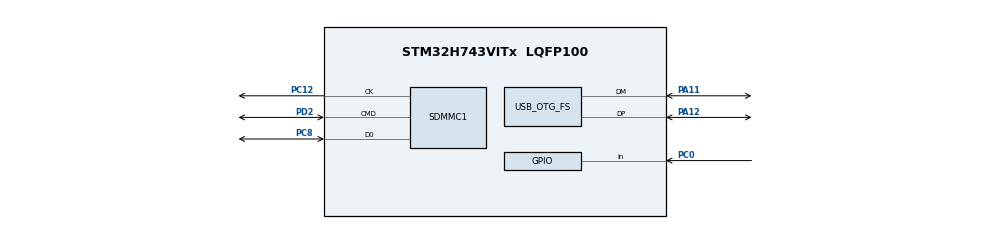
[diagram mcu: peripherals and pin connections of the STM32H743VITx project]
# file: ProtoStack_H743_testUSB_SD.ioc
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FATFS.USE_DMA_CODE_SD=1
Mcu.Family=STM32H7
Mcu.Name=STM32H743VITx
Mcu.Package=LQFP100
NVIC.OTG_FS_IRQn=true\:0\:0\:false\:false\:true\:true\:true\:true
NVIC.PriorityGroup=NVIC_PRIORITYGROUP_4
NVIC.SDMMC1_IRQn=true\:0\:0\:false\:false\:true\:true\:true\:true
PA11.GPIO_Speed=GPIO_SPEED_FREQ_VERY_HIGH
PA11.Mode=Device_Only
PA11.Signal=USB_OTG_FS_DM
PA12.GPIO_Speed=GPIO_SPEED_FREQ_VERY_HIGH
PA12.Mode=Device_Only
PA12.Signal=USB_OTG_FS_DP
PA13\ (JTMS/SWDIO).Mode=Trace_Asynchronous_SW
PA13\ (JTMS/SWDIO).Signal=DEBUG_JTMS-SWDIO
PA14\ (JTCK/SWCLK).Mode=Trace_Asynchronous_SW
PA14\ (JTCK/SWCLK).Signal=DEBUG_JTCK-SWCLK
PB3\ (JTDO/TRACESWO).Mode=Trace_Asynchronous_SW
PB3\ (JTDO/TRACESWO).Signal=DEBUG_JTDO-SWO
PC0.GPIO_PuPd=GPIO_PULLUP
PC0.Signal=GPIO_Input
PC12.GPIO_PuPd=GPIO_PULLUP
PC12.Mode=SD_1_bit
PC12.Signal=SDMMC1_CK
PC8.GPIO_PuPd=GPIO_PULLUP
PC8.Mode=SD_1_bit
PC8.Signal=SDMMC1_D0
PD2.GPIO_PuPd=GPIO_PULLUP
PD2.Mode=SD_1_bit
PD2.Signal=SDMMC1_CMD
PH0-OSC_IN\ (PH0).Mode=HSE-External-Oscillator
PH0-OSC_IN\ (PH0).Signal=RCC_OSC_IN
PH1-OSC_OUT\ (PH1).Mode=HSE-External-Oscillator
PH1-OSC_OUT\ (PH1).Signal=RCC_OSC_OUT
ProjectManager.HeapSize=0x800
ProjectManager.StackSize=0x1600
ProjectManager.TargetToolchain=STM32CubeIDE
RCC.ADCFreq_Value=96000000
RCC.APB1Freq_Value=120000000
RCC.APB2Freq_Value=120000000
RCC.APB3Freq_Value=120000000
RCC.APB4Freq_Value=120000000
RCC.CortexFreq_Value=480000000
RCC.D1PPRE=RCC_APB3_DIV2
RCC.D2PPRE1=RCC_APB1_DIV2
RCC.D2PPRE2=RCC_APB2_DIV2
RCC.D3PPRE=RCC_APB4_DIV2
RCC.DIVM1=4
RCC.DIVM2=16
RCC.DIVN1=160
RCC.DIVN2=128
RCC.DIVR2=8
RCC.EnbaleCSS=true
RCC.HCLKFreq_Value=240000000
RCC.HPRE=RCC_HCLK_DIV2
RCC.HSE_VALUE=24000000
RCC.PLLSourceVirtual=RCC_PLLSOURCE_HSE
RCC.SDMMC1CLockSelection=RCC_SDMMCCLKSOURCE_PLL2
RCC.SYSCLKFreq_VALUE=480000000
RCC.SYSCLKSource=RCC_SYSCLKSOURCE_PLLCLK
RCC.USBCLockSelection=RCC_USBCLKSOURCE_HSI48
RCC.USBFreq_Value=48000000
SDMMC1.ClockDiv=1
USB_DEVICE.CLASS_NAME_FS=MSC
USB_DEVICE.MSC_MEDIA_PACKET-MSC_FS=512
USB_DEVICE.VirtualMode-MSC_FS=Msc
USB_DEVICE.VirtualModeFS=Msc_FS
USB_OTG_FS.VirtualMode=Device_Only
VP_FATFS_VS_SDIO.Mode=SDIO
VP_USB_DEVICE_VS_USB_DEVICE_MSC_FS.Mode=MSC_FS
board=custom

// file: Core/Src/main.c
/* USER CODE BEGIN Header */
/**
  ******************************************************************************
  * @file           : main.c
  * @brief          : Main program body
  ******************************************************************************
  * @attention
  *
  * Copyright (c) 2023 STMicroelectronics.
  * All rights reserved.
  *
  * This software is licensed under terms that can be found in the LICENSE file
  * in the root directory of this software component.
  * If no LICENSE file comes with this software, it is provided AS-IS.
  *
  ******************************************************************************
  */
/* USER CODE END Header */
#include "main.h"
#include "fatfs.h"
#include "sdmmc.h"
#include "usb_device.h"
#include "gpio.h"

void SystemClock_Config(void);

int main(void)
{

  /* MCU Configuration--------------------------------------------------------*/

  /* Reset of all peripherals, Initializes the Flash interface and the Systick. */
  HAL_Init();

  /* Configure the system clock */
  SystemClock_Config();

  /* Initialize all configured peripherals */
  MX_GPIO_Init();
  MX_SDMMC1_SD_Init();
  MX_FATFS_Init();
  MX_USB_DEVICE_Init();

  /* USER CODE BEGIN 2 */

//  HAL_SD_InitCard(&hsd1);
//  HAL_SD_CardInfoTypeDef info;
//  HAL_SD_GetCardInfo(&hsd1, &info);
//  __NOP();
  /* USER CODE END 2 */

  /* Infinite loop */
  while (1)
  {

  }
}

void SystemClock_Config(void)
{
  RCC_OscInitTypeDef RCC_OscInitStruct = {0};
  RCC_ClkInitTypeDef RCC_ClkInitStruct = {0};

  /** Supply configuration update enable
  */
  HAL_PWREx_ConfigSupply(PWR_LDO_SUPPLY);

  /** Configure the main internal regulator output voltage
  */
  __HAL_PWR_VOLTAGESCALING_CONFIG(PWR_REGULATOR_VOLTAGE_SCALE1);

  while(!__HAL_PWR_GET_FLAG(PWR_FLAG_VOSRDY)) {}

  __HAL_RCC_SYSCFG_CLK_ENABLE();
  __HAL_PWR_VOLTAGESCALING_CONFIG(PWR_REGULATOR_VOLTAGE_SCALE0);

  while(!__HAL_PWR_GET_FLAG(PWR_FLAG_VOSRDY)) {}

  /** Macro to configure the PLL clock source
  */
  __HAL_RCC_PLL_PLLSOURCE_CONFIG(RCC_PLLSOURCE_HSE);

  /** Initializes the RCC Oscillators according to the specified parameters
  * in the RCC_OscInitTypeDef structure.
  */
  RCC_OscInitStruct.OscillatorType = RCC_OSCILLATORTYPE_HSI48|RCC_OSCILLATORTYPE_HSE;
  RCC_OscInitStruct.HSEState = RCC_HSE_ON;
  RCC_OscInitStruct.HSI48State = RCC_HSI48_ON;
  RCC_OscInitStruct.PLL.PLLState = RCC_PLL_ON;
  RCC_OscInitStruct.PLL.PLLSource = RCC_PLLSOURCE_HSE;
  RCC_OscInitStruct.PLL.PLLM = 4;
  RCC_OscInitStruct.PLL.PLLN = 160;
  RCC_OscInitStruct.PLL.PLLP = 2;
  RCC_OscInitStruct.PLL.PLLQ = 2;
  RCC_OscInitStruct.PLL.PLLR = 2;
  RCC_OscInitStruct.PLL.PLLRGE = RCC_PLL1VCIRANGE_2;
  RCC_OscInitStruct.PLL.PLLVCOSEL = RCC_PLL1VCOWIDE;
  RCC_OscInitStruct.PLL.PLLFRACN = 0;
  if (HAL_RCC_OscConfig(&RCC_OscInitStruct) != HAL_OK)
  {
    Error_Handler();
  }

  /** Initializes the CPU, AHB and APB buses clocks
  */
  RCC_ClkInitStruct.ClockType = RCC_CLOCKTYPE_HCLK|RCC_CLOCKTYPE_SYSCLK
                              |RCC_CLOCKTYPE_PCLK1|RCC_CLOCKTYPE_PCLK2
                              |RCC_CLOCKTYPE_D3PCLK1|RCC_CLOCKTYPE_D1PCLK1;
  RCC_ClkInitStruct.SYSCLKSource = RCC_SYSCLKSOURCE_PLLCLK;
  RCC_ClkInitStruct.SYSCLKDivider = RCC_SYSCLK_DIV1;
  RCC_ClkInitStruct.AHBCLKDivider = RCC_HCLK_DIV2;
  RCC_ClkInitStruct.APB3CLKDivider = RCC_APB3_DIV2;
  RCC_ClkInitStruct.APB1CLKDivider = RCC_APB1_DIV2;
  RCC_ClkInitStruct.APB2CLKDivider = RCC_APB2_DIV2;
  RCC_ClkInitStruct.APB4CLKDivider = RCC_APB4_DIV2;

  if (HAL_RCC_ClockConfig(&RCC_ClkInitStruct, FLASH_LATENCY_4) != HAL_OK)
  {
    Error_Handler();
  }

  /** Enables the Clock Security System
  */
  HAL_RCC_EnableCSS();
}

void Error_Handler(void)
{
  __disable_irq();
  while (1)
  {
  }
}
